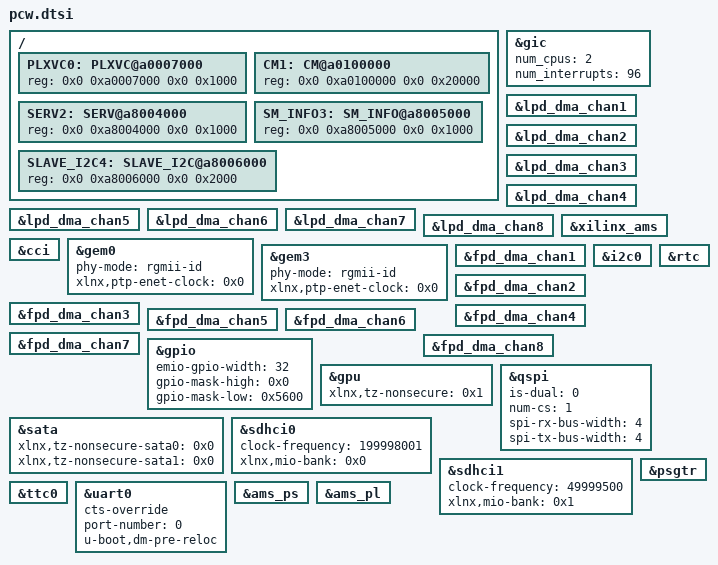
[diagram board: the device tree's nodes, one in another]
/*
 * CAUTION: This file is automatically generated by Xilinx.
 * Version: XSCT 
 * Today is: Tue May  7 02:12:28 2024
 */


&gic {
	num_cpus = <2>;
	num_interrupts = <96>;
};
&lpd_dma_chan1 {
	status = "okay";
};
&lpd_dma_chan2 {
	status = "okay";
};
&lpd_dma_chan3 {
	status = "okay";
};
&lpd_dma_chan4 {
	status = "okay";
};
&lpd_dma_chan5 {
	status = "okay";
};
&lpd_dma_chan6 {
	status = "okay";
};
&lpd_dma_chan7 {
	status = "okay";
};
&lpd_dma_chan8 {
	status = "okay";
};
&xilinx_ams {
	status = "okay";
};
&cci {
	status = "okay";
};
&gem0 {
	phy-mode = "rgmii-id";
	status = "okay";
	xlnx,ptp-enet-clock = <0x0>;
};
&gem3 {
	phy-mode = "rgmii-id";
	status = "okay";
	xlnx,ptp-enet-clock = <0x0>;
};
&fpd_dma_chan1 {
	status = "okay";
};
&fpd_dma_chan2 {
	status = "okay";
};
&fpd_dma_chan3 {
	status = "okay";
};
&fpd_dma_chan4 {
	status = "okay";
};
&fpd_dma_chan5 {
	status = "okay";
};
&fpd_dma_chan6 {
	status = "okay";
};
&fpd_dma_chan7 {
	status = "okay";
};
&fpd_dma_chan8 {
	status = "okay";
};
&gpio {
	emio-gpio-width = <32>;
	gpio-mask-high = <0x0>;
	gpio-mask-low = <0x5600>;
	status = "okay";
};
&gpu {
	status = "okay";
	xlnx,tz-nonsecure = <0x1>;
};
&i2c0 {
	status = "okay";
};
&qspi {
	is-dual = <0>;
	num-cs = <1>;
	spi-rx-bus-width = <4>;
	spi-tx-bus-width = <4>;
	status = "okay";
};
&rtc {
	status = "okay";
};
&sata {
	status = "okay";
	xlnx,tz-nonsecure-sata0 = <0x0>;
	xlnx,tz-nonsecure-sata1 = <0x0>;
};
&sdhci0 {
	clock-frequency = <199998001>;
	status = "okay";
	xlnx,mio-bank = <0x0>;
};
&sdhci1 {
	clock-frequency = <49999500>;
	status = "okay";
	xlnx,mio-bank = <0x1>;
};
&psgtr {
	status = "okay";
};
&ttc0 {
	status = "okay";
};
&uart0 {
	cts-override ;
	device_type = "serial";
	port-number = <0>;
	status = "okay";
	u-boot,dm-pre-reloc ;
};
/ {
	PLXVC0: PLXVC@a0007000 {
		reg = <0x0 0xa0007000 0x0 0x1000>;
	};
	CM1: CM@a0100000 {
		reg = <0x0 0xa0100000 0x0 0x20000>;
	};
	SERV2: SERV@a8004000 {
		reg = <0x0 0xa8004000 0x0 0x1000>;
	};
	SM_INFO3: SM_INFO@a8005000 {
		reg = <0x0 0xa8005000 0x0 0x1000>;
	};
	SLAVE_I2C4: SLAVE_I2C@a8006000 {
		reg = <0x0 0xa8006000 0x0 0x2000>;
	};
};
&ams_ps {
	status = "okay";
};
&ams_pl {
	status = "okay";
};
